# nrf7140_wificore register map
Vendor: Nordic Semiconductor; Series: nRF71; File version: 1
Registers are 32-bit, read-write, reset 0x0 unless marked. A register's access mark holds for its fields unless they carry their own. Offsets are from the block's base; [hi:lo] are bit positions; lines under a group give offsets from that group; {n}, {i} and the like mark numbered series.

## RPUPHY (part 4 of 8) — WIFICore RPU PHY peripherals
Base 0x48080000; alternate view of RPUMAC
0xA000 WIFICOREAGC group — Unspecified
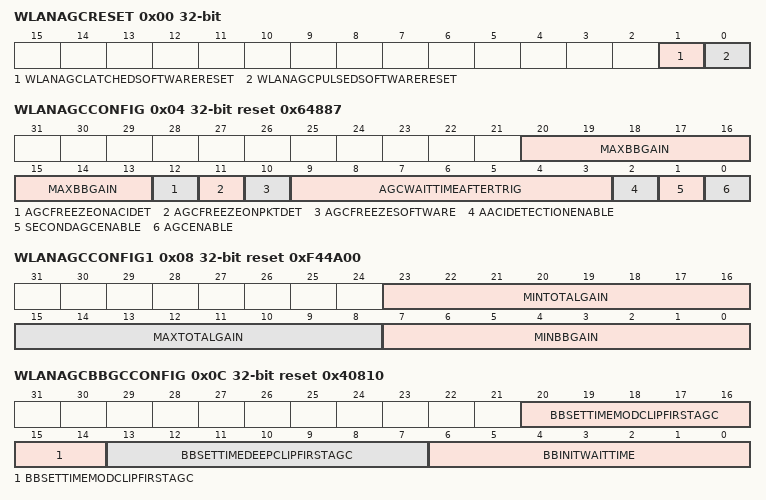
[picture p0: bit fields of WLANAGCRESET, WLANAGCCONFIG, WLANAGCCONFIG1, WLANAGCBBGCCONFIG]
  0x00 WLANAGCRESET
    [1] WLANAGCLATCHEDSOFTWARERESET — Latched software reset.
    [0] WLANAGCPULSEDSOFTWARERESET — Self-clearing software reset.
  0x04 WLANAGCCONFIG reset 0x64887
    [20:13] MAXBBGAIN — This value (in dB) indicates the Maximum Gain we can setin BaseBand. Value ranges between -128 and 127.
    [12] AGCFREEZEONACIDET — When enabled, the AGC will be freezed for the duration where aciDetected from ED module is active.
      0=Disable; 1=Enable
    [11] AGCFREEZEONPKTDET — When enabled, the AGC will be freezed for the duration where pktDetected from ED module is active.
      0=Disable; 1=Enable
    [10] AGCFREEZESOFTWARE — When enabled, the LNA and BB gain are frozen at the current level and all AGC triggers will be ignored.
      0=Disable; 1=Enable
    [9:3] AGCWAITTIMEAFTERTRIG — After a new AGC trigger is received, the number of ADC samples to wait before kicking off the gain control process. This is to let the analog components to ramp up/down to the new packet power.
    [2] AACIDETECTIONENABLE — Enable for Non-adjacent channel interferer detection. AACI (Alternate Adjacent Channel Interference) is a legacy term. This logic enables early identification of the interferer and prevent pktDetected by ED module on those interfering packets.
      0=Disable; 1=Enable
    [1] SECONDAGCENABLE — Switch to control whether second AGC on the HT/VHT/HE-stf fields should be done or not. If disabled, then the first AGC gain will continue till the end of packet.
      0=Disable; 1=Enable
    [0] AGCENABLE — Bit field to enable AGC module. When AGC is disabled, the RF gain at the point in time will take effect and will not be modified.
      0=Disable; 1=Enable
  0x08 WLANAGCCONFIG1 reset 0xF44A00
    [23:16] MINTOTALGAIN — Min allowed Total gain in dB. (total gain = lna gain dB + bb gain dB).Value ranges between -128 and 127.
    [15:8] MAXTOTALGAIN — Max allowed Total gain in dB. (total gain = lna gain dB + bb gain dB).Value ranges between -128 and 127.
    [7:0] MINBBGAIN — This value (in dB) indicates the Minimum Gain we can setin BaseBand. Value ranges between -128 and 127.
  0x0C WLANAGCBBGCCONFIG reset 0x40810
    [20:14] BBSETTIMEMODCLIPFIRSTAGC — Settling time in number of ADC samples after changing current BB gain in response to MODERATE clipping scenario during first AGC operation (on L-STF field for OFDM packets).Value ranges between 0 and 127.
    [13:7] BBSETTIMEDEEPCLIPFIRSTAGC — Settling time in number of ADC samples after changing current BB gain in response to DEEP clipping scenario during first AGC operation (on L-STF field for OFDM packets).Value ranges between 0 and 127.
    [6:0] BBINITWAITTIME — Settling time in number of ADC samples after changing from current BB gain to bbInitGain.Value ranges between 0 and 127.
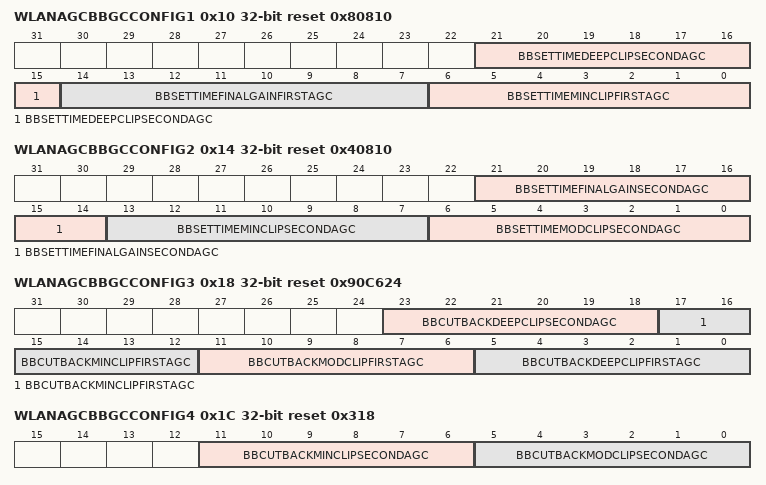
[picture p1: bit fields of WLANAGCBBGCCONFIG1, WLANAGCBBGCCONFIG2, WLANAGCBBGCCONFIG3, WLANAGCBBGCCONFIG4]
  0x10 WLANAGCBBGCCONFIG1 reset 0x80810
    [21:15] BBSETTIMEDEEPCLIPSECONDAGC — Settling time in number of ADC samples after changing current BB gain in response to DEEP clipping scenario during second AGC operation (on HT/VHT/HE-STF field for OFDM packets).Value ranges between 0 and 127.
    [14:7] BBSETTIMEFINALGAINFIRSTAGC — Settling time in number of ADC samples after changing current BB gain to final gain during first AGC operation (on L-STF field for OFDM packets).Value ranges between 0 and 255.
    [6:0] BBSETTIMEMINCLIPFIRSTAGC — Settling time in number of ADC samples after changing current BB gain in response to MINIMUM clipping scenario during first AGC operation (on L-STF field for OFDM packets).Value ranges between 0 and 127.
  0x14 WLANAGCBBGCCONFIG2 reset 0x40810
    [21:14] BBSETTIMEFINALGAINSECONDAGC — Settling time in number of ADC samples after changing current BB gain to final gain during second AGC operation(on HT/VHT/HE-STF field for OFDM packets).Value ranges between 0 and 255.
    [13:7] BBSETTIMEMINCLIPSECONDAGC — Settling time in number of ADC samples after changing current BB gain in response to MINIMUM clipping scenario during second AGC operation(on HT/VHT/HE-STF field for OFDM packets).Value ranges between 0 and 127.
    [6:0] BBSETTIMEMODCLIPSECONDAGC — Settling time in number of ADC samples after changing current BB gain in response to MODERATE clipping scenario during second AGC operation(on HT/VHT/HE-STF field for OFDM packets).Value ranges between 0 and 127.
  0x18 WLANAGCBBGCCONFIG3 reset 0x90C624
    [23:18] BBCUTBACKDEEPCLIPSECONDAGC — BB Gain in dB to be cutback for DEEP clip scenario during second AGC operation(on HT/VHT/HE-STF field for OFDM packets).Value ranges between 0 and 63 dB.
    [17:12] BBCUTBACKMINCLIPFIRSTAGC — BB Gain in dB to be cutback for MINIMUM clip scenario during first AGC operation(on L-STF field for OFDM packets).Value ranges between 0 and 63 dB.
    [11:6] BBCUTBACKMODCLIPFIRSTAGC — BB Gain in dB to be cutback for MODERATE clip scenario during first AGC operation(on L-STF field for OFDM packets).Value ranges between 0 and 63 dB.
    [5:0] BBCUTBACKDEEPCLIPFIRSTAGC — BB Gain in dB to be cutback for DEEP clip scenario during first AGC operation(on L-STF field for OFDM packets).Value ranges between 0 and 63 dB.
  0x1C WLANAGCBBGCCONFIG4 reset 0x318
    [11:6] BBCUTBACKMINCLIPSECONDAGC — BB Gain in dB to be cutback for MINIMUM clip scenario during second AGC operation(on HT/VHT/HE-STF field for OFDM packets). Value ranges between 0 and 63 dB.
    [5:0] BBCUTBACKMODCLIPSECONDAGC — BB Gain in dB to be cutback for MODERATE clip scenario during second AGC operation(on HT/VHT/HE-STF field for OFDM packets).Value ranges between 0 and 63 dB.
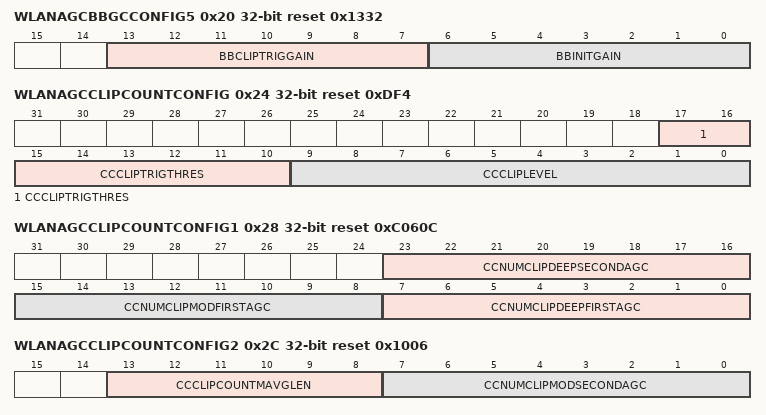
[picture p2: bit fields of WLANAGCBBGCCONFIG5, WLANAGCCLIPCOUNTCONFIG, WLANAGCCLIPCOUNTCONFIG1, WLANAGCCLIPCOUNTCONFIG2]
  0x20 WLANAGCBBGCCONFIG5 reset 0x1332
    [13:7] BBCLIPTRIGGAIN — The initial Baseband gain in dB to be set in response to clip trigger or variance too high trigger. This value is smaller than the BB_INIT_GAIN as we know that signal is already above the optimal bit occupancy and hence want to start AGC search with a cutdown value.Value ranges between 0 and 127.
    [6:0] BBINITGAIN — The initial Baseband gain in dB to be set after powering on AGC and in response to variance too low trigger.Value ranges between 0 and 127.
  0x24 WLANAGCCLIPCOUNTCONFIG reset 0xDF4
    [17:10] CCCLIPTRIGTHRES — The min clip count to be considered as clip trigger - to start AGC gain search.Value ranges between 0 and 255.
    [9:0] CCCLIPLEVEL — The maximum value of ADC output beyond which clip is declared. This maximum value setting is valid for both I and Q samples at the output of ADC.
  0x28 WLANAGCCLIPCOUNTCONFIG1 reset 0xC060C
    [23:16] CCNUMCLIPDEEPSECONDAGC — Minimum Number of clips to decide the occurence of deep saturation at second AGC.. Value ranges between 0 and 255.
    [15:8] CCNUMCLIPMODFIRSTAGC — Minimum Number of clips to decide the occurence of moderate saturation at first AGC.. Value ranges between 0 and 255.
    [7:0] CCNUMCLIPDEEPFIRSTAGC — Minimum Number of clips to decide the occurence of deep saturation at first AGC. Value ranges between 0 and 255.
  0x2C WLANAGCCLIPCOUNTCONFIG2 reset 0x1006
    [13:8] CCCLIPCOUNTMAVGLEN — Clip The window size (number of contiguous IQ samples) to be considered for counting the clips for Clip trigger.Value ranges between 0 and 63.
    [7:0] CCNUMCLIPMODSECONDAGC — Minimum Number of clips to decide the occurence of moderate saturation at second AGC.. Value ranges between 0 and 255.
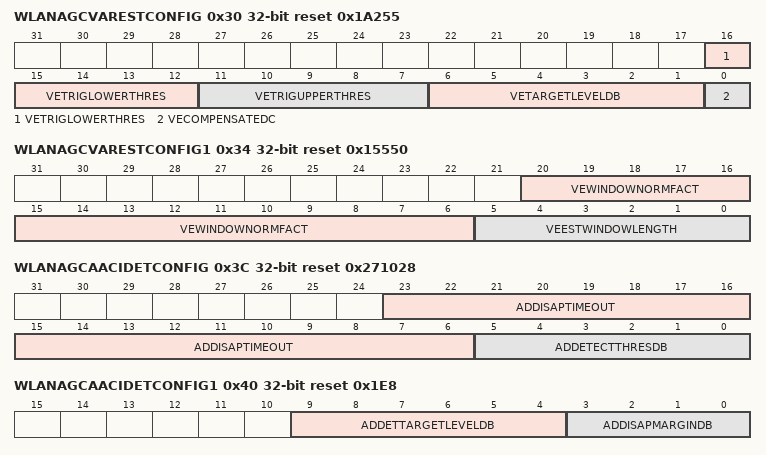
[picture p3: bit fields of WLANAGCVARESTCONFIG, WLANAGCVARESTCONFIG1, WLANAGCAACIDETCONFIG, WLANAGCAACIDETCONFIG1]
  0x30 WLANAGCVARESTCONFIG reset 0x1A255
    [16:12] VETRIGLOWERTHRES — A variance trigger will be issued if current variance goes below TARGET_LEVEL_DB + TRIG_LOWER_THRES.It has a range of -16 .. 15. Default value is -6.
    [11:7] VETRIGUPPERTHRES — A variance trigger will be issued if current variance goes above TARGET_LEVEL_DB + TRIG_UPPER_THRES.It has a range of -16 .. 15. Default value is 4.
    [6:1] VETARGETLEVELDB — The optimum variance in dB of the ADC samples to be achieved by the AGC search. This is done on the ADC samples (after DC subtraction if COMPENSATE_DC is enabled). It has a range of 0 .. 63.
    [0] VECOMPENSATEDC — Bit field to enable DC compensation. Flag to control if the IQ samples are to be compensated for the DC before further power/clipping measurements.
      0=Disable; 1=Enable
  0x34 WLANAGCVARESTCONFIG1 reset 0x15550
    [20:6] VEWINDOWNORMFACT — Normalisation factor for the sum of products in the variance estimation. The total number of products per window is equal to VE_EST_WINDOW_LENGTH - 4.It has a format of u1.14. Default value is 1365.
    [5:0] VEESTWINDOWLENGTH — Variance estimation window length in number of samples.It has a range of 0 .. 63. Default value is 16.
  0x38 WLANAGCVARESTCONFIG2 reset 0x2F
    [5:0] VERSSICOMPFACTOR — The value in dB to be subtracted from agcVarDb to get the estimate of RF input signal power in the inband. (See VE_WINDOW_NORM_FACT description). agcRssiDb = agcVarDb - agcTotalGainDb - VE_RSSI_COMP_FACTOR.It has a range of 0 .. 63. Default value is 47.
  0x3C WLANAGCAACIDETCONFIG reset 0x271028
    [23:6] ADDISAPTIMEOUT — The count in number of ADC input samples before with an AACI disappeared timeOut trigger will be issued, so the AGC gains are re-initialized and AGC operation is performed. This is used for the cases where disappearance of AACI signal is not detectable by the fall of agcVarDb (as the AACI leakage power is below the LNA noise floor).It has a range of 0 .. 262143. Default value is 40000.
    [5:0] ADDETECTTHRESDB — AACI Detection threshold. If the (lnaRssiDb - agcRssiDb) > AD_DETECT_THRES_DB, the aaciDetected signal is asserted.It has a range of 0 .. 63. Default value is 40.
  0x40 WLANAGCAACIDETCONFIG1 reset 0x1E8
    [9:4] ADDETTARGETLEVELDB — Provisional register to shift the target level of the agcVarDb when AACI signal is detected. This may be required for avoiding multiple AGC triggers when AACI signal has a variance > VE_TRIG_UPPER_THRES/VE_TRIG_LOWER_THRES.It has a range of 0 .. 63. Default value is 30.
    [3:0] ADDISAPMARGINDB — The amount in dB by which the agcVarDb should fall in order for it to be confirmed as AACI signal disappearance. This disappearance check is enabled aaciDetected is high.It has a range of 0 .. 15. Default value is 8.
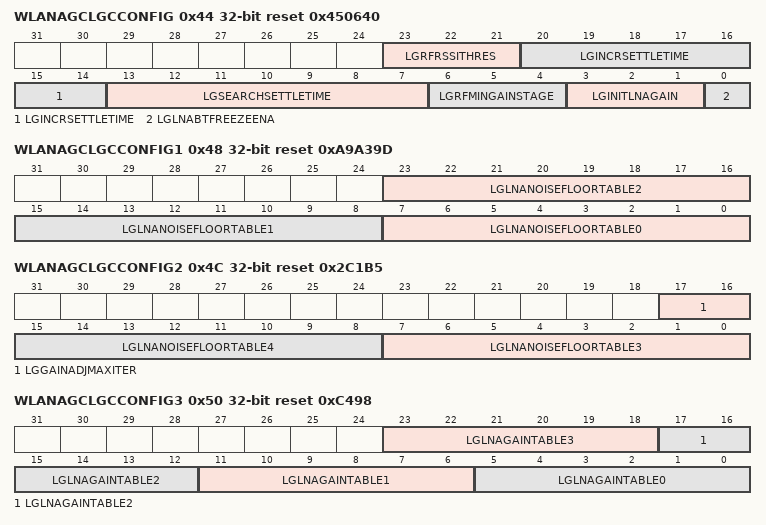
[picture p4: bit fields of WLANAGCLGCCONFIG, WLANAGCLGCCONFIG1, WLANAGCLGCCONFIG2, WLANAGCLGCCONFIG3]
  0x44 WLANAGCLGCCONFIG reset 0x450640
    [23:21] LGRFRSSITHRES — The threshold above which the RF Rssi value that is feedback from RF (a 3 bit value from 0-7) is considered to be saturating the LNA and hence LNA gain needs to be lowered.It has a range of 0 .. 7. Default value is 2.
    [20:14] LGINCRSETTLETIME — The number of samples to wait for the signal level to settle after WLAN increment.It has a range of 0 .. 127. Default value is 20.
    [13:7] LGSEARCHSETTLETIME — The number of samples to wait for the signal level to settle after LNA gain change.It has a range of 0 .. 127. Default value is 12.
    [6:4] LGRFMINGAINSTAGE — The LNA gain stage which has the min Gain in DB. This is also the stage that has the max stage idx. In sheliak and vega this is stage 4 (-12dB).It has a range of 0 .. 4. Default value is 4.
    [3:1] LGINITLNAGAIN — The initial LNA gain stage to be used (start of the day and after every clip/variance trigger). Stage numbers 0 through 4 are valid. This is 3-bit valueDefault value is 0.
    [0] LGLNABTFREEZEENA — Flag to determine if the LNA gain should be freezed when btFreeze signal is high (from BT module). IF this flag is disabled, then even if btFreeze is high, the LNA gain will be changed based on the needs of wlanAgc.
  0x48 WLANAGCLGCCONFIG1 reset 0xA9A39D
    [23:16] LGLNANOISEFLOORTABLE2 — The noise floor in dBm (noise power) corresponding to the LNA gain stage 2.This value of 8-bit signed is the noise floor expressed in dBm. Default value is -90.
    [15:8] LGLNANOISEFLOORTABLE1 — The noise floor in dBm (noise power) corresponding to the LNA gain stage 1.This value of 8-bit signed is the noise floor expressed in dBm. Default value is -96.
    [7:0] LGLNANOISEFLOORTABLE0 — The noise floor in dBm (noise power) corresponding to the LNA gain stage 0.This value of 8-bit signed is the noise floor expressed in dBm. Default value is -98.
  0x4C WLANAGCLGCCONFIG2 reset 0x2C1B5
    [17:16] LGGAINADJMAXITER — The number of (check_rf_rssi_value, reduce_lna_gain, wait for gain settle) cycles before the search is stopped.It has a range of 0 .. 3. Default value is 2.
    [15:8] LGLNANOISEFLOORTABLE4 — The noise floor in dBm (noise power) corresponding to the LNA gain stage 4.This value of 8-bit signed is the noise floor expressed in dBm. Default value is -64.
    [7:0] LGLNANOISEFLOORTABLE3 — The noise floor in dBm (noise power) corresponding to the LNA gain stage 3.This value of 8-bit signed is the noise floor expressed in dBm. Default value is -76.
  0x50 WLANAGCLGCCONFIG3 reset 0xC498
    [23:18] LGLNAGAINTABLE3 — This value of 6-bit signed is the LNA gain for stage 3. Default value is 0.
    [17:12] LGLNAGAINTABLE2 — This value of 6-bit signed is the LNA gain for stage 2. Default value is 12.
    [11:6] LGLNAGAINTABLE1 — This value of 6-bit signed is the LNA gain for stage 1. Default value is 18.
    [5:0] LGLNAGAINTABLE0 — This value of 6-bit signed is the LNA gain for stage 0. Default value is 24.
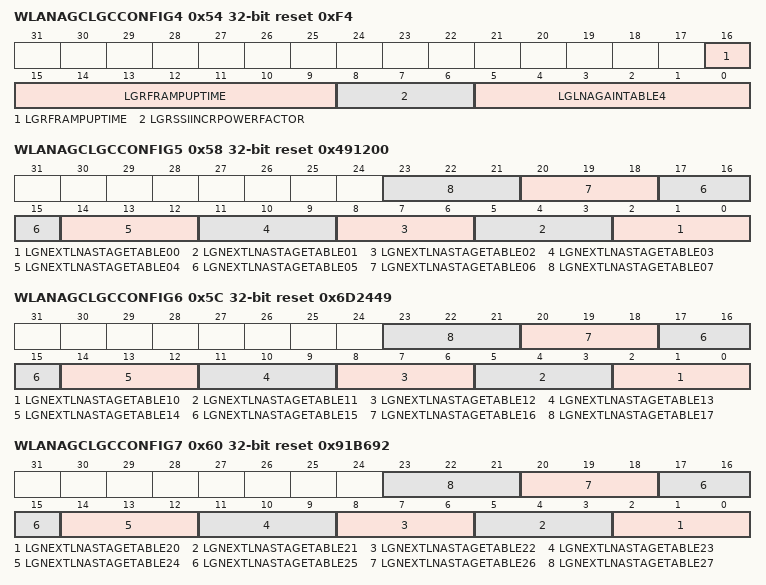
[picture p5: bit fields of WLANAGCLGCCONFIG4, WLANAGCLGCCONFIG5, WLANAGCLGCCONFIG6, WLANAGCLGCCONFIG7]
  0x54 WLANAGCLGCCONFIG4 reset 0xF4
    [16:9] LGRFRAMPUPTIME — Holds number of samples to wait for before starting LNA gain search. This value is set to zero currently as the ramp up time is handled by AGC_WAIT_TIME_AFTER_TRIG.It has a range of 0 .. 127. Default value is 0.
    [8:6] LGRSSIINCRPOWERFACTOR — The 3-bit RF_RSSI_VAL feedback from RF increments by 1 for every LG_RSSI_INCR_POWER_FACTOR increase in LNA input signal power in dBm. Unit is dB. For vega this value is 3.It has a range of 0 .. 7. Default value is 3.
    [5:0] LGLNAGAINTABLE4 — This value of 6-bit signed is the LNA gain for stage 4. Default value is -12.
  0x58 WLANAGCLGCCONFIG5 reset 0x491200
    [3n+2:3n] LGNEXTLNASTAGETABLE{n:02} (n=0..7) — The stage index of the next LNA stage to use, if the current lna stage is 0 and rf rssi value is {n}.It has a range of 0 .. 7.
  0x5C WLANAGCLGCCONFIG6 reset 0x6D2449
    [3n-28:3n-30] LGNEXTLNASTAGETABLE{n} (n=10..17) — The stage index of the next LNA stage to use, if the current lna stage is 1 and rf rssi value is {n-10}.It has a range of 0 .. 7.
  0x60 WLANAGCLGCCONFIG7 reset 0x91B692
    [3n-58:3n-60] LGNEXTLNASTAGETABLE{n} (n=20..27) — The stage index of the next LNA stage to use, if the current lna stage is 2 and rf rssi value is {n-20}.It has a range of 0 .. 7.
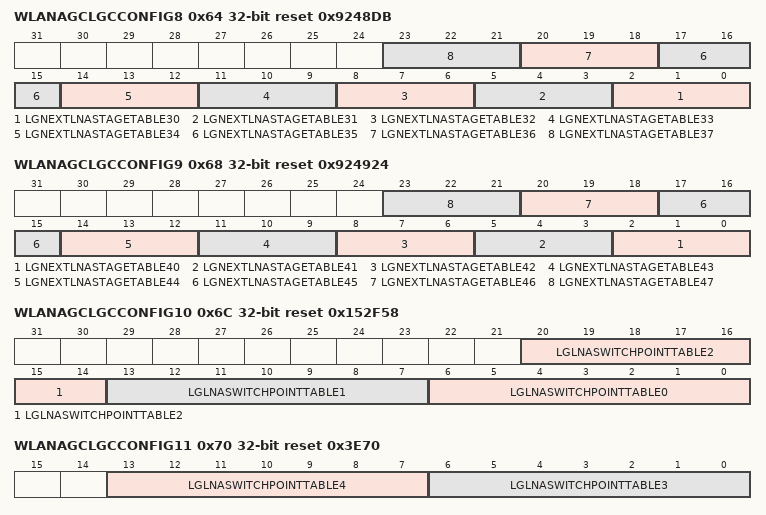
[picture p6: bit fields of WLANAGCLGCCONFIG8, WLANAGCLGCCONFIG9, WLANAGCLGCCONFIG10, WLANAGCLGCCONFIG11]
  0x64 WLANAGCLGCCONFIG8 reset 0x9248DB
    [3n-88:3n-90] LGNEXTLNASTAGETABLE{n} (n=30..37) — The stage index of the next LNA stage to use, if the current lna stage is 3 and rf rssi value is {n-30}.It has a range of 0 .. 7.
  0x68 WLANAGCLGCCONFIG9 reset 0x924924
    [3n-118:3n-120] LGNEXTLNASTAGETABLE{n} (n=40..47) — The stage index of the next LNA stage to use, if the current lna stage is 4 and rf rssi value is {n-40}.It has a range of 0 .. 7.
  0x6C WLANAGCLGCCONFIG10 reset 0x152F58
    [20:14] LGLNASWITCHPOINTTABLE2 — lnaSwitchPointDbm for LNA stage 2, where lnaSwitchPointDbm is defined as:The value of RF input power in dBm which meets the following equation:rfRssiVal3Bit = lnaSwitchPointDbm + LG_RSSI_INCR_POWER_FACTOR * (rfInPowerDbm - lnaSwitchPointDbm)'This value is 7-bit signed. Default value is -28.
    [13:7] LGLNASWITCHPOINTTABLE1 — lnaSwitchPointDbm for LNA stage 1, where lnaSwitchPointDbm is defined as:The value of RF input power in dBm which meets the following equation:rfRssiVal3Bit = lnaSwitchPointDbm + LG_RSSI_INCR_POWER_FACTOR * (rfInPowerDbm - lnaSwitchPointDbm)'This value is 7-bit signed. Default value is -34.
    [6:0] LGLNASWITCHPOINTTABLE0 — lnaSwitchPointDbm for LNA stage 0, where lnaSwitchPointDbm is defined as:The value of RF input power in dBm which meets the following equation:rfRssiVal3Bit = lnaSwitchPointDbm + LG_RSSI_INCR_POWER_FACTOR * (rfInPowerDbm - lnaSwitchPointDbm)'This value is 7-bit signed. Default value is -40.
  0x70 WLANAGCLGCCONFIG11 reset 0x3E70
    [13:7] LGLNASWITCHPOINTTABLE4 — lnaSwitchPointDbm for LNA stage 4, where lnaSwitchPointDbm is defined as:The value of RF input power in dBm which meets the following equation:rfRssiVal3Bit = lnaSwitchPointDbm + LG_RSSI_INCR_POWER_FACTOR * (rfInPowerDbm - lnaSwitchPointDbm)'This value is 7-bit signed. Default value is -4.
    [6:0] LGLNASWITCHPOINTTABLE3 — lnaSwitchPointDbm for LNA stage 3, where lnaSwitchPointDbm is defined as:The value of RF input power in dBm which meets the following equation:rfRssiVal3Bit = lnaSwitchPointDbm + LG_RSSI_INCR_POWER_FACTOR * (rfInPowerDbm - lnaSwitchPointDbm)'This value is 7-bit signed. Default value is -16.
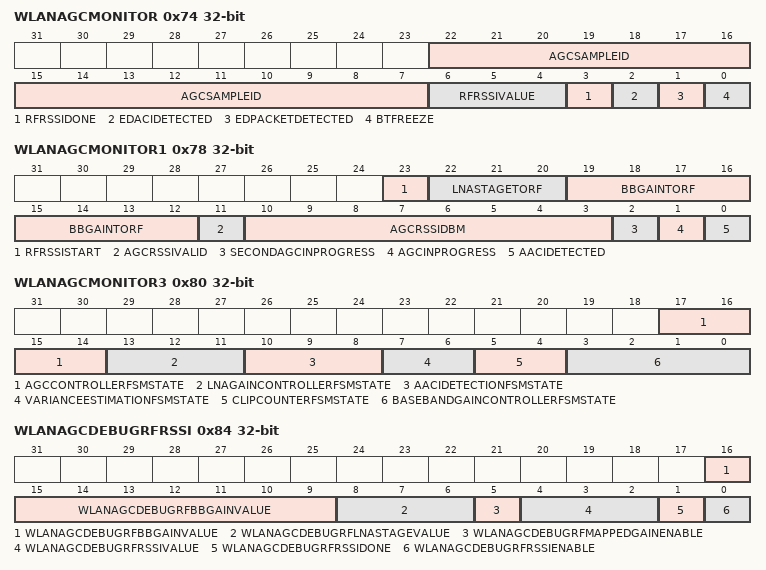
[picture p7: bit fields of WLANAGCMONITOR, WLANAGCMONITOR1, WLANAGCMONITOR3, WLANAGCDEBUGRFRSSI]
  0x74 WLANAGCMONITOR ro
    [22:7] AGCSAMPLEID — AGC sample index.
    [6:4] RFRSSIVALUE — From RF module, the 3-bit RF RSSI value where a higher value like 7 indicates severe saturation at LNA output. This is an 3-bit signed.
    [3] RFRSSIDONE — From RF module, indicates the completion of RSSI value computation.
    [2] EDACIDETECTED — ACI detected signal from ED module. This can be used for freezing the AGC gain. So that AGC doesn't enter trigger->search->settle cycle multiple times, thereby reducing the blind period.
    [1] EDPACKETDETECTED — '1' indicates either OFDM/DSSS packet has been detected and TD processing is in progress.
    [0] BTFREEZE — Input signal from BT module where '1' indicates the BT wants the LNA gain not to be changed.
      0=Disable; 1=Enable
  0x78 WLANAGCMONITOR1 ro
    [23] RFRSSISTART — From AGC module to RF, requesting fresh computation of 3-bit RF RSSI value to determine if LNA is saturating.
    [22:20] LNASTAGETORF — LNA gain stage to the RF Module from AGC (0-4)
    [19:12] BBGAINTORF — Baseband gain (VGA) to the RF module from AGC
    [11] AGCRSSIVALID
    [10:3] AGCRSSIDBM — Inband RSSI at antenna input as seen by the AGC module. This is computed on the ADC output samples.
    [2] SECONDAGCINPROGRESS — From AGC module, indicated Second AGC gain adjustment is in progress.
    [1] AGCINPROGRESS — From AGC module, indicated AGC gain adjustment is in progress, so the ED Module will be in reset.
    [0] AACIDETECTED — From AGC module to ED, indicating AACI signal detected, which will be then used to control packet detection and CCA busy assertion.
  0x7C WLANAGCMONITOR2 ro
    [7:0] TOTALGAINDB — The sum of BB gain in dB and LNA gain in dB.
  0x80 WLANAGCMONITOR3 ro
    [17:14] AGCCONTROLLERFSMSTATE
      0=Idle; 1=InitBbGainSetup; 2=TriggerState; 3=WaitAftTrig; 4=WaitForLgcDone; 5=TrigOptBbGain; 6=AaciDet; 7=SagcAftTrig; 8=SagcOptBbGain
    [13:11] LNAGAINCONTROLLERFSMSTATE
      0=Init; 1=TRIG_INCR_DECR_FREEZE; 2=GainAdjustWait; 3=GainAdjustIter; 4=WlanIncrWait
    [10:8] AACIDETECTIONFSMSTATE
      0=Idle; 1=DoAaciCheck; 2=CheckAaciDisapDet; 3=IncrLnaGain; 4=WAIT_FOR_AGC_RSSI_UPDATE; 5=WaitForReadjDone; 6=WaitForAaciDisap
    [7:6] VARIANCEESTIMATIONFSMSTATE
      0=Idle; 1=WaitForVarTrig; 2=WaitForOneshot
    [5:4] CLIPCOUNTERFSMSTATE
      0=Idle; 1=WaitForClipTrig; 2=WaitForOneshot
    [3:0] BASEBANDGAINCONTROLLERFSMSTATE
      0=Idle; 1=DoGainInit; 2=WAIT_FOR_GAIN_SETTLE_INIT; 3=GAIN_CHANGE_DONE_INIT; 4=WAIT_FOR_INIT_DONE_ACK; 5=OptGainIterInit; 6=EstSigLevel; 7=WaitForGainSettle7 (WAIT_FOR_GAIN_SETTLE_VAR_EST); 8=ReadjGainInit; 9=WaitForGainSettle9 (WAIT_FOR_GAIN_SETTLE_READJ)
  0x84 WLANAGCDEBUGRFRSSI
    [16:9] WLANAGCDEBUGRFBBGAINVALUE — This field overwrites the bbGainToRf value to RF module. s7.0.
    [8:6] WLANAGCDEBUGRFLNASTAGEVALUE — This field overwrites the lnaStageToRf value to RF module. u3.0.
    [5] WLANAGCDEBUGRFMAPPEDGAINENABLE — This field enables the overwrites of the RF lnaStageToRf and bbGainToRf signals to RF module.
    [4:2] WLANAGCDEBUGRFRSSIVALUE — This field overwrites the 3-bit RF RSSI value From RF module. Higher value like 7 indicates severe saturation at LNA output. This is an 3-bit signed.
    [1] WLANAGCDEBUGRFRSSIDONE — This field overwrites the RF RSSI valid signal (the completion of RSSI value computation) From RF module.
    [0] WLANAGCDEBUGRFRSSIENABLE — This field enables the overwrites of the RF RSSI done and value signals from RF module.
0xB000 WLAN_VITERBI group — Unspecified
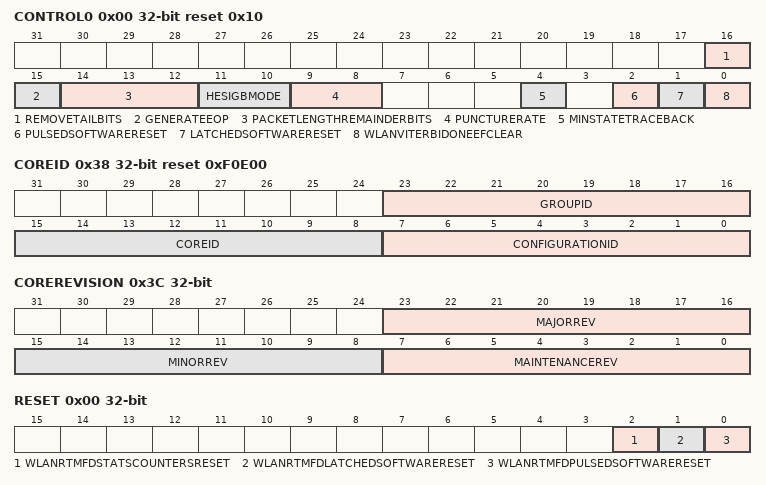
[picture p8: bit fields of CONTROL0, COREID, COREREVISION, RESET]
  0x00 CONTROL0 reset 0x10 — WLAN VITERBI CONTROL0
    [16] REMOVETAILBITS
      0=Output data bytes contain tail bits; 1=TailBitsAreNotOutput
    [15] GENERATEEOP
      0=Don't generate an EOP flag at the end of the packet; 1=Generate an EOP flag at the end of the packet
    [14:12] PACKETLENGTHREMAINDERBITS — PACKET_LENGTH_REMAINDER_BITS Options are
      0=0Bits; 1=1Bit; 2=2Bits; 4=4Bits; 5=5Bits; 6=6Bits; 7=3Bits
    [11:10] HESIGBMODE — HESIGB_MODEOptions are
      0=NormalVhtPacket; 1=HE-SIG-B uncompressed 20/40 MHz ppduBW (18-bit common field, 52-bit User block field); 2=HeSigBUncompressed2 (HE-SIG-B uncompressed 80 MHz ppduBw (27-bit common field, 52-bit User block field)); 3=HE-SIG-B compressed (no common field, 52-bit User block field)
    [9:8] PUNCTURERATE — PUNCTURE_RATEOptions are
      0=Rate12; 1=Rate23; 2=Rate34; 3=Rate56
    [4] MINSTATETRACEBACK
      0=Trace back from zero state; 1=Trace back from minimum state
    [2] PULSEDSOFTWARERESET — 0 : Do nothing1 : Apply a pulsed software resetThis bit is automatically returns to 0
    [1] LATCHEDSOFTWARERESET
      0=RemoveReset; 1=ApplyReset
    [0] WLANVITERBIDONEEFCLEAR — 0 : Do nothing1 : Clear the event flag WLAN_VITERBI_DONE_EF_STATUSThis bit automatically returns to 0
  0x04 CONTROL1 — WLAN VITERBI CONTROL1
    [23:0] PACKETLENGTHBYTES — Packet length in bytes
  0x08 START — WLAN VITERBI START
    [0] VITERBIACTIVE — ACTIVE=0 when the Wi-Fi Vietrbi is idle, and ACTIVE=1 when the Wi-Fi Viterbi is active.When ACTIVE==1, writing to this bit has no effect.When ACTIVE= =0, writing ACTIVE= 1 causes the Wi-Fi Viterbi to start an operation using theparameters set in the registers above.ACTIVE automatically returns to 0 when the Viterbi operation completes after last trace back
  0x14 IPDMATBUSCONTROL — WLAN VITERBI IPDMA TBUS CONTROL
    [20] IPDMATBUSSTALLWHENCOMPLETE — Controls whether TBus write port stalls upstream when the Viterbi job is complete:
      0=Viterbi TBus write port discards data when the Viterbi job is complete; 1=ViterbiTbusWritePort1 (Viterbi TBus write port stalls upstream when the Viterbi job is complete)
  0x34 STATUS ro — WLAN VITERBI STATUS
    [0] WLANVITERBIDONEEFSTATUS — WLAN_VITERBI_DONE_EF_STATUS is set to 1 when an VITERBI operation completes,and is cleared when 1 is written to WLAN_VITERBI_DONE_EF_CLEAR in the WLAN_VITERBI_CONTROL0 register.
  0x38 COREID ro reset 0xF0E00 — WLAN VITERBI CORE ID
    [23:16] GROUPID — Identifies core as part of an IMG IP family group. [0x0F = UCC]
    [15:8] COREID — Identifies the member of the IP group. [0x0E = Wireless LAN Viterbi]
    [7:0] CONFIGURATIONID — Configuration of the core.
  0x3C COREREVISION ro — WLAN VITERBI CORE REVISION
    [23:16] MAJORREV — Family Major Release Revision.
    [15:8] MINORREV — Core Minor Release Revision.
    [7:0] MAINTENANCEREV — Maintenance Release Revision.
0xC000 WLAN_RTM_FD group — Unspecified
  0x00 RESET — WLAN RTM FD RESET
    [2] WLANRTMFDSTATSCOUNTERSRESET — Self-clearing software reset for the statistics counters.
    [1] WLANRTMFDLATCHEDSOFTWARERESET — Latched software reset.
    [0] WLANRTMFDPULSEDSOFTWARERESET — Self-clearing software reset.
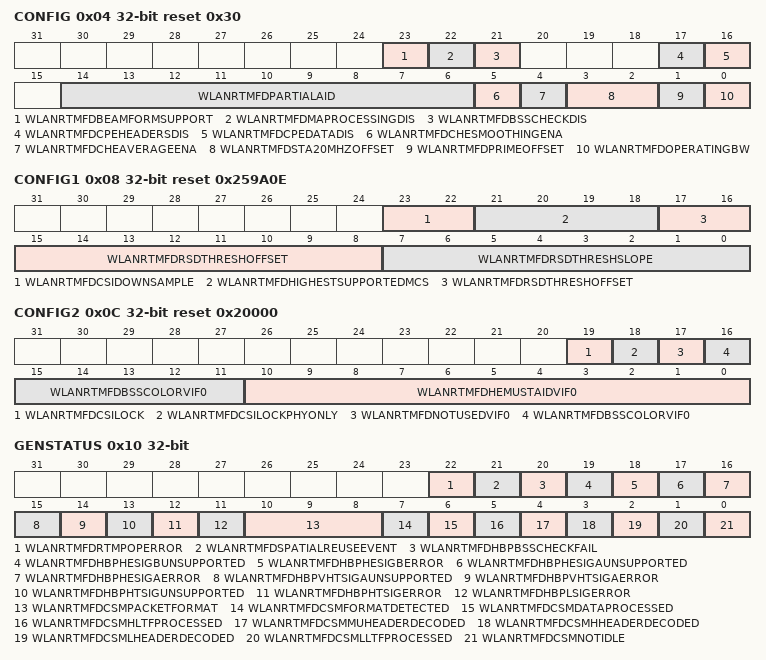
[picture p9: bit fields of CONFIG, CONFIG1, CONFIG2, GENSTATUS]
  0x04 CONFIG reset 0x30 — WLAN RTM FD CONFIG
    [23] WLANRTMFDBEAMFORMSUPPORT — Enable support for Beamforming. When disabled the unsupported flag will be rised when a NDP is detected.
    [22] WLANRTMFDMAPROCESSINGDIS — Disable midambles processing. When disabled the MIMO Channel Estimation matrix is not updated for the midambles.
    [21] WLANRTMFDBSSCHECKDIS — Disable BSS association checks: PARTIAL_AID and BSS_COLOR.
    [17] WLANRTMFDCPEHEADERSDIS — Disable CPE compensation for headers OFDM symbols.
    [16] WLANRTMFDCPEDATADIS — Disable CPE compensation for data OFDM symbols.
    [14:6] WLANRTMFDPARTIALAID — Partial association ID : combination of the association ID and the BSSID.
    [5] WLANRTMFDCHESMOOTHINGENA — Enable / disable channel estimation smoothing.
    [4] WLANRTMFDCHEAVERAGEENA — Enable / disable L-LTF and L-SIG channel estimations average. L-LTF estimation is output when the average is disabled.
    [3:2] WLANRTMFDSTA20MHZOFFSET — Selects the 20MHz partition of the BSS operating bandwidth (up to 80 MHz supported):0-1: when BSS operating bandwidth is 400-3: when BSS operating bandwidth is 80
    [1] WLANRTMFDPRIMEOFFSET — Prime offset for 40 MHz operating bandwidth:
      0=Low; 1=High
    [0] WLANRTMFDOPERATINGBW — Receiver operating bandwidth:
      0=20Mhz; 1=40Mhz
  0x08 CONFIG1 reset 0x259A0E — WLAN RTM FD CONFIG 1
    [23:22] WLANRTMFDCSIDOWNSAMPLE — CSI_DOWNSAMPLE:
      0=NoDownsample; 1=DownsampleBy2; 2=DownsampleBy4
    [21:18] WLANRTMFDHIGHESTSUPPORTEDMCS — Configure the highest supported MCS: detected packets with MCS greater than WLAN_RTM_FD_HIGHEST_SUPPORTED_MCS will be dropped.NOTE: the final highest MCS will be the minimum of this register and the internal value (i.e. HT: 7, VHT: 8 for SigBW20, 9 for SigBW40, HE-SU/MU: 9, HE-ER: 2 for SigBW20, 0 for SigBW40
    [17:8] WLANRTMFDRSDTHRESHOFFSET — Repeated L-SIG detector SNR threshold interpolation offset:threshold =WLAN_RTM_FD_RSD_THRESH_SLOPE * SNRdB + WLAN_RTM_FD_RSD_THRESH_OFFSET
    [7:0] WLANRTMFDRSDTHRESHSLOPE — Repeated L-SIG detector SNR threshold interpolation slope:threshold =WLAN_RTM_FD_RSD_THRESH_SLOPE * SNRdB + WLAN_RTM_FD_RSD_THRESH_OFFSET
  0x0C CONFIG2 reset 0x20000 — WLAN RTM FD CONFIG 2
    [19] WLANRTMFDCSILOCK — CSI lock value, use when WLAN_RTM_FD_CSI_LOCK_PHY_ONLY is set.
    [18] WLANRTMFDCSILOCKPHYONLY — Set when MAC is not present; WLAN_RTM_FD_CSI_LOCK is used.
    [17] WLANRTMFDNOTUSEDVIF0 — Set to mark the VIF0 as not used: STA-ID and BSS color will be ignored.
    [16:11] WLANRTMFDBSSCOLORVIF0 — VIF0 - BSS color of the BSS of which the STA is a member.
    [10:0] WLANRTMFDHEMUSTAIDVIF0 — VIF0 - STA identifier for HE-MU
  0x10 GENSTATUS ro — WLAN RTM FD GEN STATUS
    [22] WLANRTMFDRTMPOPERROR — Indicates POP error event in the RTM-FD.
    [21] WLANRTMFDSPATIALREUSEEVENT — Indicates Spatial Reuse is detected.
    [20] WLANRTMFDHBPBSSCHECKFAIL — Indicates BSS association check failure:- VHT : PARTIAL_AID not matching WLAN_RTM_FD_PARTIAL_AID- HE-SU/HE-ER : BSS_COLOR not matching WLAN_RTM_FD_BSS_COLOR- HE-MU : STA-ID not matching WLAN_RTM_FD_HEMU_STA_ID or not matchig broadcast STA-IDsNote: PARTIAL_AID and BSS_COLOR checks can be disabled by setting WLAN_RTM_FD_BSS_CHECK_DIS register to 1
    [19] WLANRTMFDHBPHESIGBUNSUPPORTED — Indicates HE-SIG-B unsupported feature:- MCS > 9- DCM = 1 if STBC = 1- NSTS > 0 if STBC = 0, NSTS > 1 if STBC = 1
    [18] WLANRTMFDHBPHESIGBERROR — Indicates HE-SIG-B decoding error (common and user fields):- invalid tail bits- CRC check failure
    [17] WLANRTMFDHBPHESIGAUNSUPPORTED — Indicates HE-SIG-A unsupported feature:[HE-SU/HE-ER]- UL detected (PPDU is addressed to an AP)- MCS > 9 if HE-SU, MCS > 2 if HE-ER and Bandwidth = 0, MCS > 0 if HE-ER and Bandwidth = 1- Bandwidth > 1- NSTS > 0 if STBC = 0, NSTS > 1 if STBC = 1- HE-TB detected[HE-MU]- HE-SIGB-MCS > 5, HE-SIGB-MCS = 2 or HE-SIGB-MC > 4 if HE-SIGB-DCM enabled- HE-LTF symbols > 8 if Doppler = 0, HE-LTF symbols > 4 if Doppler = 1
    [16] WLANRTMFDHBPHESIGAERROR — Indicates HE-SIG-A decoding error:- invalid reserved bits- invalid tail bits- CRC check failure- mod(L-SIG[length], 3) == 0
    [15] WLANRTMFDHBPVHTSIGAUNSUPPORTED — Indicates VHT-SIG-A unsupported feature:- Bandwidth > 1- Group ID not 0 or 63 (VHT-MU)- NSTS > 0 if STBC = 0, NSTS > 1 if STBC = 1- MCS > 8 if Bandwidth = 0, MCS > 9 if Bandwidth = 1
    [14] WLANRTMFDHBPVHTSIGAERROR — Indicates VHT-SIG-A decoding error:- invalid reserved bits- invalid tail bits- CRC check failure
    [13] WLANRTMFDHBPHTSIGUNSUPPORTED — Indicates HT-SIG unsupported feature:- MCS > 7- STBC > 1
    [12] WLANRTMFDHBPHTSIGERROR — Indicates HT-SIG decoding error:- invalid reserved bits- invalid tail bits- CRC check failure
    [11] WLANRTMFDHBPLSIGERROR — Indicates L-SIG decoding error:- invalid rate- invalid reserved bits- invalid tail bits- parity check failure
    [10:8] WLANRTMFDCSMPACKETFORMAT — Packet format:
      0=LLegacy; 1=Ht; 2=Reserve (This is reserved.); 3=Vht; 4=HeSu; 5=HeMu; 6=HeEr; 7=HeTb
    [7] WLANRTMFDCSMFORMATDETECTED — Indicates the packet format is detected (valid)
    [6] WLANRTMFDCSMDATAPROCESSED — Indicates all the data OFDM symbols are output to the RXP : L-DATA / HT-DATA / VHT-DATA / HE-DATA
    [5] WLANRTMFDCSMHLTFPROCESSED — Indicates the non-legacy LTF fields processing is completed : HT-LTF / VHT-LTF / HE-LTFestimated channel
    [4] WLANRTMFDCSMMUHEADERDECODED — Indicates the multi-user header is decoded (when it applies) : VHT-SIG-B / HE-SIG-B
    [3] WLANRTMFDCSMHHEADERDECODED — Indicates the non-legacy header is decoded (when it applies) : HT-SIG / VHT-SIG-A / HE-SIG-A
    [2] WLANRTMFDCSMLHEADERDECODED — Indicates the legacy header is decoded : L-SIG
    [1] WLANRTMFDCSMLLTFPROCESSED — Indicates the legacy LTF fields processing is completed : L-LTF estimated channel
    [0] WLANRTMFDCSMNOTIDLE — Indicates the training mode - frequency domain is not idle (i.e. processing packet)
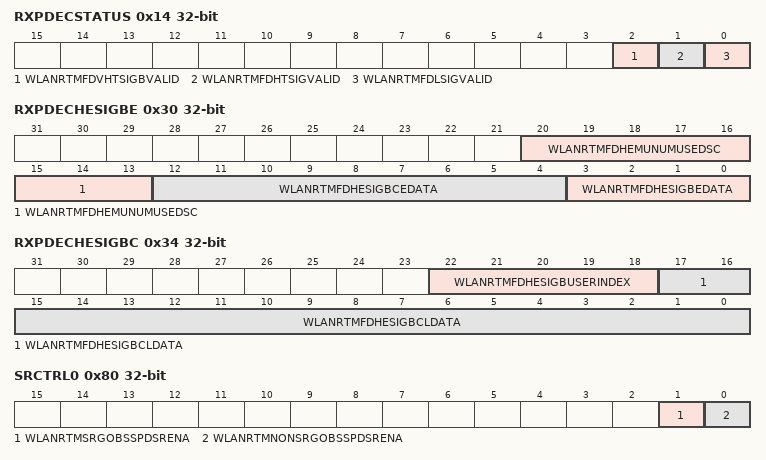
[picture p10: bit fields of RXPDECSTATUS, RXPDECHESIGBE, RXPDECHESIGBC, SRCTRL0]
  0x14 RXPDECSTATUS — WLAN RTM FD RXPDEC STATUS
    [2] WLANRTMFDVHTSIGBVALID — Indicates when the VHT-SIG-B decoded data is available.Note: this register is cleared when soft-reset
    [1] WLANRTMFDHTSIGVALID — Indicates when the HT-SIG / VHT-SIG_A / HE-SIG-A decoded data is available.Note: this register is cleared when soft-reset
    [0] WLANRTMFDLSIGVALID — Indicates when the L-SIG decoded data is available.Note: this register is cleared when soft-reset
  0x18 RXPDECLSIG — WLAN RTM FD RXPDEC LSIG
    [23:0] WLANRTMFDLSIGDATA — L-SIG decoded data - bits 23 .. 0
  0x1C RXPDECHTSIGL — WLAN RTM FD RXPDEC HTSIG L
    [23:0] WLANRTMFDHTSIGLDATA — HT-SIG / VHT-SIG-A / HE-SIG-A1 decoded data - bits 23 .. 0
  0x20 RXPDECHTSIGH — WLAN RTM FD RXPDEC HTSIG H
    [23:0] WLANRTMFDHTSIGHDATA — HT-SIG / VHT-SIG-A / HE-SIG-A decoded data - bits 47 .. 24
  0x24 RXPDECHESIGAE — WLAN RTM FD RXPDEC HESIGA E
    [3:0] WLANRTMFDHESIGAEDATA — HE-SIG-A decoded data - bits 51 .. 48
  0x28 RXPDECVHTSIGBL — WLAN RTM FD RXPDEC VHTSIGB L
    [23:0] WLANRTMFDVHTSIGBLDATA — VHT-SIG-B / HE-SIG-B decoded data - bits 23 .. 0
  0x2C RXPDECVHTSIGBH — WLAN RTM FD RXPDEC VHTSIGB H
    [23:0] WLANRTMFDVHTSIGBHDATA — VHT-SIG-B / HE-SIG-B decoded data - bits 47 .. 24
  0x30 RXPDECHESIGBE — WLAN RTM FD RXPDEC HESIGB E
    [20:13] WLANRTMFDHEMUNUMUSEDSC — HE-MU number of used sub-carriers
    [12:4] WLANRTMFDHESIGBCEDATA — HE-SIG-B common field data - bits 26 .. 18
    [3:0] WLANRTMFDHESIGBEDATA — HE-SIG-B decoded data - bits 51 .. 48
  0x34 RXPDECHESIGBC — WLAN RTM FD RXPDEC HESIGB C
    [22:18] WLANRTMFDHESIGBUSERINDEX — HE-SIG-B user field index
    [17:0] WLANRTMFDHESIGBCLDATA — HE-SIG-B common field data - bits 17 .. 0
  0x38 STATSCOUNTER0 — WLAN RTM FD STATS COUNTER 0
    [23:0] WLANRTMOFDMCORRELATIONPASSCOUNT — Number of detected OFDM packets.
  0x3C STATSCOUNTER1 — WLAN RTM FD STATS COUNTER 1
    [23:0] WLANRTMLTFCORRELATIONFAILCOUNT — Number of OFDM packets failed FSB detection - peak not found or peak below the threshold.
  0x40 STATSCOUNTER2 — WLAN RTM FD STATS COUNTER 2
    [23:0] WLANRTMLSIGDECODEFAILCOUNT — Number of OFDM packets failed L-SIG checks - parity or other conditions.
  0x44 STATSCOUNTER3 — WLAN RTM FD STATS COUNTER 3
    [23:0] WLANRTMHTSIGDECODEFAILCOUNT — Number of OFDM packets failed HT-SIG checks - CRC or other conditions.
  0x48 STATSCOUNTER4 — WLAN RTM FD STATS COUNTER 4
    [23:0] WLANRTMVHTSIGADECODEFAILCOUNT — Number of OFDM packets failed VHT-SIG-A checks - CRC or other conditions.
  0x4C STATSCOUNTER5 — WLAN RTM FD STATS COUNTER 5
    [23:0] WLANRTMHESIGADECODEFAILCOUNT — Number of OFDM packets failed HE-SIG-A checks - CRC or other conditions.
  0x50 STATSCOUNTER6 — WLAN RTM FD STATS COUNTER 6
    [23:0] WLANRTMHESIGBDECODEFAILCOUNT — Number of OFDM packets failed HE-SIG-B checks - CRC or other conditions.
  0x54 FRAMECOUNTER0 — WLAN RTM FD FRAME COUNTER 0
    [23:0] WLANRTMLEGACYFRAMECOUNT — Number of Legacy frames received - increments when the last DATA symbol is sent to the RXP.
  0x58 FRAMECOUNTER1 — WLAN RTM FD FRAME COUNTER 1
    [23:0] WLANRTMHTFRAMECOUNT — Number of HT frames received - increments when the last DATA symbol is sent to the RXP.
  0x5C FRAMECOUNTER2 — WLAN RTM FD FRAME COUNTER 2
    [23:0] WLANRTMVHTFRAMECOUNT — Number of VHT frames received - increments when the last DATA symbol is sent to the RXP.
  0x60 FRAMECOUNTER3 — WLAN RTM FD FRAME COUNTER 3
    [23:0] WLANRTMHESUFRAMECOUNT — Number of HE-SU frames received - increments when the last DATA symbol is sent to the RXP.
  0x64 FRAMECOUNTER4 — WLAN RTM FD FRAME COUNTER 4
    [23:0] WLANRTMHEERFRAMECOUNT — Number of HE-ER-SU frames received - increments when the last DATA symbol is sent to the RXP.
  0x68 FRAMECOUNTER5 — WLAN RTM FD FRAME COUNTER 5
    [23:0] WLANRTMHEMUFRAMECOUNT — Number of HE-MU frames received - increments when the last DATA symbol is sent to the RXP.
  0x6C FRAMECOUNTER6 — WLAN RTM FD FRAME COUNTER 6
    [23:0] WLANRTMUNSUPPORTEDFRAMECOUNT — Number of received OFDM packets with unsupporterd features - increments when fields of HT-SIG / VHT-SIG-A /HE-SIG-A / HE-SIG-B indicate capabilities/features that are not supported by STA and header is succesfully decoded.
  0x70 FRAMECOUNTER7 — WLAN RTM FD FRAME COUNTER 7
    [23:0] WLANRTMOTHERSTAFRAMECOUNT — Number of received OFDM packets where packet ID not matcing the STA ID - increments when Partial AID (VHT), BSS Color (HE-SU/HE-ER-SU) or User Field (HE-MU) not matching the configured value and header is succesfully decoded.
  0x74 FRAMECOUNTER8 — WLAN RTM FD FRAME COUNTER 8
    [23:0] WLANRTMVHTNDPFRAMECOUNT — Number of VHT NDP frames received - increments when the last VHT-LTF symbol is sent to the SVD.
  0x78 FRAMECOUNTER9 — WLAN RTM FD FRAME COUNTER 9
    [23:0] WLANRTMHESUNDPFRAMECOUNT — Number of HE-SU NDP frames received - increments when the last HE-LTF symbol is sent to the SVD.
  0x7C STATSCOUNTER7 — WLAN RTM FD STATS COUNTER 7
    [23:0] WLANRTMS2LTIMEOUTFAILCOUNT — Number of OFDM packets failed due to missing S2L event.
  0x80 SRCTRL0 — WLAN RTM FD SR CTRL 0
    [1] WLANRTMSRGOBSSPDSRENA — Enable spatial reuse in overlapping-BSS with preamble detection in spatial reuse group cases.
    [0] WLANRTMNONSRGOBSSPDSRENA — Enable spatial reuse in overlapping-BSS with preamble detection in non-spatial reuse group cases.
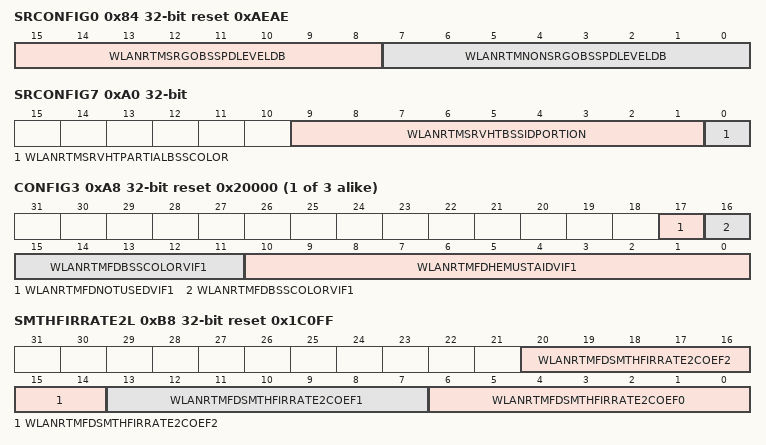
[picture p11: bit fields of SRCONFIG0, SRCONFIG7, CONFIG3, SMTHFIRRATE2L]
  0x84 SRCONFIG0 reset 0xAEAE — WLAN RTM FD SR CONFIG 0
    [15:8] WLANRTMSRGOBSSPDLEVELDB — Preamble detection level in dBm for spatial reuse group cases (s7.0). Valid Range : -82 to -62 dBm
    [7:0] WLANRTMNONSRGOBSSPDLEVELDB — Preamble detection level in dBm for non spatial reuse group cases (s7.0). Valid Range : -82 to -62 dBm
  0x88 SRCONFIG1 — WLAN RTM FD SR CONFIG 1
    [23:0] WLANRTMSRGPARTIALBSSIDBITMAP0 — Indicates the Partial BSSID values used by members of the SRG of which the transmitting STA is a member - bits 23 downto 0. Note: Each bit of the bitmap corresponds to one of the 64 possible values of BSSID[39:44], where the lowest numbered bit corresponds to Partial BSSID value 0 and the highest numbered bit corresponds to Partial BSSID value 63
  0x8C SRCONFIG2 — WLAN RTM FD SR CONFIG 2
    [23:0] WLANRTMSRGPARTIALBSSIDBITMAP1 — Indicates the Partial BSSID values used by members of the SRG of which the transmitting STA is a member - bits 47 downto 24. Note: Each bit of the bitmap corresponds to one of the 64 possible values of BSSID[39:44], where the lowest numbered bit corresponds to Partial BSSID value 0 and the highest numbered bit corresponds to Partial BSSID value 63
  0x90 SRCONFIG3 — WLAN RTM FD SR CONFIG 3
    [15:0] WLANRTMSRGPARTIALBSSIDBITMAP2 — Indicates the Partial BSSID values used by members of the SRG of which the transmitting STA is a member - bits 63 downto 48. Note: Each bit of the bitmap corresponds to one of the 64 possible values of BSSID[39:44], where the lowest numbered bit corresponds to Partial BSSID value 0 and the highest numbered bit corresponds to Partial BSSID value 63
  0x94 SRCONFIG4 — WLAN RTM FD SR CONFIG 4
    [23:0] WLANRTMSRGBSSCOLORBITMAP0 — Indicates the BSS color values used by members of the SRG of which the transmitting STA is a member - bits 23 downto 0. Note: Each bit of the bitmap corresponds to one of the 64 BSS colors, where the lowest numbered bit corresponds to BSS color value 0 and the highest numbered bit corresponds to BSS color value 63.The bit in the bitmap that corresponds to the BSS color value 0 is reserved
  0x98 SRCONFIG5 — WLAN RTM FD SR CONFIG 5
    [23:0] WLANRTMSRGBSSCOLORBITMAP1 — Indicates the BSS color values used by members of the SRG of which the transmitting STA is a member - bits 47 downto 24. Note: Each bit of the bitmap corresponds to one of the 64 BSS colors, where the lowest numbered bit corresponds to BSS color value 0 and the highest numbered bit corresponds to BSS color value 63.The bit in the bitmap that corresponds to the BSS color value 0 is reserved
  0x9C SRCONFIG6 — WLAN RTM FD SR CONFIG 6
    [15:0] WLANRTMSRGBSSCOLORBITMAP2 — Indicates the BSS color values used by members of the SRG of which the transmitting STA is a member - bits 63 downto 48. Note: Each bit of the bitmap corresponds to one of the 64 BSS colors, where the lowest numbered bit corresponds to BSS color value 0 and the highest numbered bit corresponds to BSS color value 63.The bit in the bitmap that corresponds to the BSS color value 0 is reserved
  0xA0 SRCONFIG7 — WLAN RTM FD SR CONFIG 7
    [9:1] WLANRTMSRVHTBSSIDPORTION — VHT specific BSSID portion
    [0] WLANRTMSRVHTPARTIALBSSCOLOR — Partial BSS color field/
  0xA4 STATSCOUNTER8 — WLAN RTM FD STATS COUNTER 8
    [23:0] WLANRTMSPATIALREUSEEVENTCOUNT — Number of Spatial Reuse events detected.
  {0x9C+4j} CONFIG{j} reset 0x20000 (j=3..5) — WLAN RTM FD CONFIG {j}
    [17] WLANRTMFDNOTUSEDVIF{j-2} — Set to mark the VIF{j-2} as not used: STA-ID and BSS color will be ignored.
    [16:11] WLANRTMFDBSSCOLORVIF{j-2} — VIF{j-2} - BSS color of the BSS of which the STA is a member.
    [10:0] WLANRTMFDHEMUSTAIDVIF{j-2} — VIF{j-2} - STA identifier for HE-MU
  0xB4 CONFIG6 — WLAN RTM FD CONFIG 6
    [10:0] WLANRTMFDHEMUBSSIDINDEX — BSSID index field for a non-transmitted BSSID; set to 0 for transmitted BSSID
  0xB8 SMTHFIRRATE2L reset 0x1C0FF — WLAN RTM FD SMTH FIR RATE2 L
    [20:14] WLANRTMFDSMTHFIRRATE2COEF2 — Smoothing FIR filter, Tu/GI rate 2, coefficient 2, s0.6, default 7
    [13:7] WLANRTMFDSMTHFIRRATE2COEF1 — Smoothing FIR filter, Tu/GI rate 2, coefficient 1, s0.6, default 1
    [6:0] WLANRTMFDSMTHFIRRATE2COEF0 — Smoothing FIR filter, Tu/GI rate 2, coefficient 0, s0.6, default -1
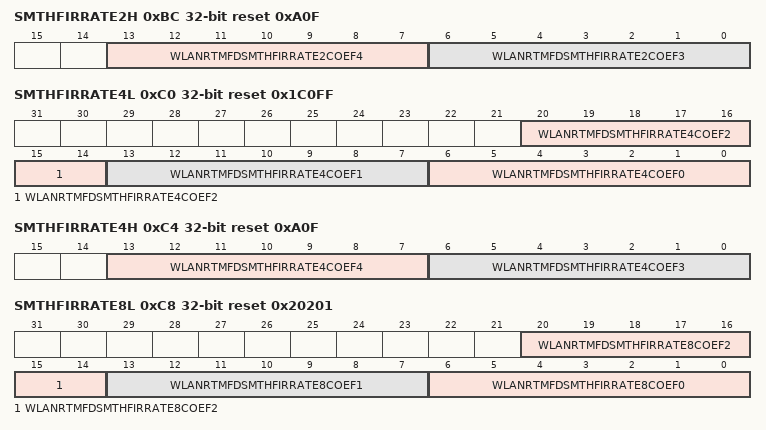
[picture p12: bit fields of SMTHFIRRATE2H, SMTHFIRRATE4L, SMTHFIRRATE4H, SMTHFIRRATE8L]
  0xBC SMTHFIRRATE2H reset 0xA0F — WLAN RTM FD SMTH FIR RATE2 H
    [13:7] WLANRTMFDSMTHFIRRATE2COEF4 — Smoothing FIR filter, Tu/GI rate 2, coefficient 4, s0.6, default 20
    [6:0] WLANRTMFDSMTHFIRRATE2COEF3 — Smoothing FIR filter, Tu/GI rate 2, coefficient 3, s0.6, default 15
  0xC0 SMTHFIRRATE4L reset 0x1C0FF — WLAN RTM FD SMTH FIR RATE4 L
    [20:14] WLANRTMFDSMTHFIRRATE4COEF2 — Smoothing FIR filter, Tu/GI rate 4, coefficient 2, s0.6, default 7
    [13:7] WLANRTMFDSMTHFIRRATE4COEF1 — Smoothing FIR filter, Tu/GI rate 4, coefficient 1, s0.6, default 1
    [6:0] WLANRTMFDSMTHFIRRATE4COEF0 — Smoothing FIR filter, Tu/GI rate 4, coefficient 0, s0.6, default -1
  0xC4 SMTHFIRRATE4H reset 0xA0F — WLAN RTM FD SMTH FIR RATE4 H
    [13:7] WLANRTMFDSMTHFIRRATE4COEF4 — Smoothing FIR filter, Tu/GI rate 4, coefficient 4, s0.6, default 20
    [6:0] WLANRTMFDSMTHFIRRATE4COEF3 — Smoothing FIR filter, Tu/GI rate 4, coefficient 3, s0.6, default 15
  0xC8 SMTHFIRRATE8L reset 0x20201 — WLAN RTM FD SMTH FIR RATE8 L
    [20:14] WLANRTMFDSMTHFIRRATE8COEF2 — Smoothing FIR filter, Tu/GI rate 8, coefficient 2, s0.6, default 8
    [13:7] WLANRTMFDSMTHFIRRATE8COEF1 — Smoothing FIR filter, Tu/GI rate 8, coefficient 1, s0.6, default 4
    [6:0] WLANRTMFDSMTHFIRRATE8COEF0 — Smoothing FIR filter, Tu/GI rate 8, coefficient 0, s0.6, default 1
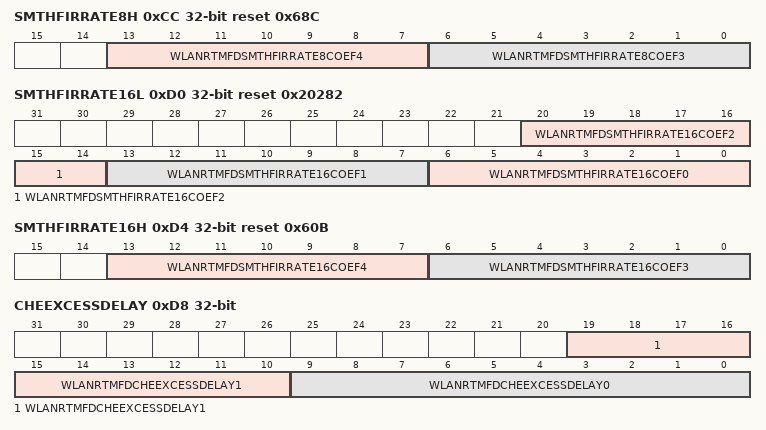
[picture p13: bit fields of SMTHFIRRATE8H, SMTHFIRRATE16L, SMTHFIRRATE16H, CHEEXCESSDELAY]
  0xCC SMTHFIRRATE8H reset 0x68C — WLAN RTM FD SMTH FIR RATE8 H
    [13:7] WLANRTMFDSMTHFIRRATE8COEF4 — Smoothing FIR filter, Tu/GI rate 8, coefficient 4, s0.6, default 13
    [6:0] WLANRTMFDSMTHFIRRATE8COEF3 — Smoothing FIR filter, Tu/GI rate 8, coefficient 3, s0.6, default 12
  0xD0 SMTHFIRRATE16L reset 0x20282 — WLAN RTM FD SMTH FIR RATE16 L
    [20:14] WLANRTMFDSMTHFIRRATE16COEF2 — Smoothing FIR filter, Tu/GI rate 16, coefficient 2, s0.6, default 8
    [13:7] WLANRTMFDSMTHFIRRATE16COEF1 — Smoothing FIR filter, Tu/GI rate 16, coefficient 1, s0.6, default 5
    [6:0] WLANRTMFDSMTHFIRRATE16COEF0 — Smoothing FIR filter, Tu/GI rate 16, coefficient 0, s0.6, default 2
  0xD4 SMTHFIRRATE16H reset 0x60B — WLAN RTM FD SMTH FIR RATE16 H
    [13:7] WLANRTMFDSMTHFIRRATE16COEF4 — Smoothing FIR filter, Tu/GI rate 16, coefficient 4, s0.6, default 12
    [6:0] WLANRTMFDSMTHFIRRATE16COEF3 — Smoothing FIR filter, Tu/GI rate 16, coefficient 3, s0.6, default 11
  0xD8 CHEEXCESSDELAY ro — WLAN RTM FD CHE EXCESS DELAY
    [19:10] WLANRTMFDCHEEXCESSDELAY1 — Excess Delay estimate at channel smoothing for the second stream, s0.9
    [9:0] WLANRTMFDCHEEXCESSDELAY0 — Excess Delay estimate at channel smoothing for the first stream, s0.9
  0xDC CHEDMALENGTH — WLAN RTM FD CHE DMA LENGTH
    [8:0] WLANRTMFDCHEDMALENGTH — Transfer specified number of channel estimates to the EDC through the channel estimates TBus read port. Register value decrements as the channel estimates are transferred.
